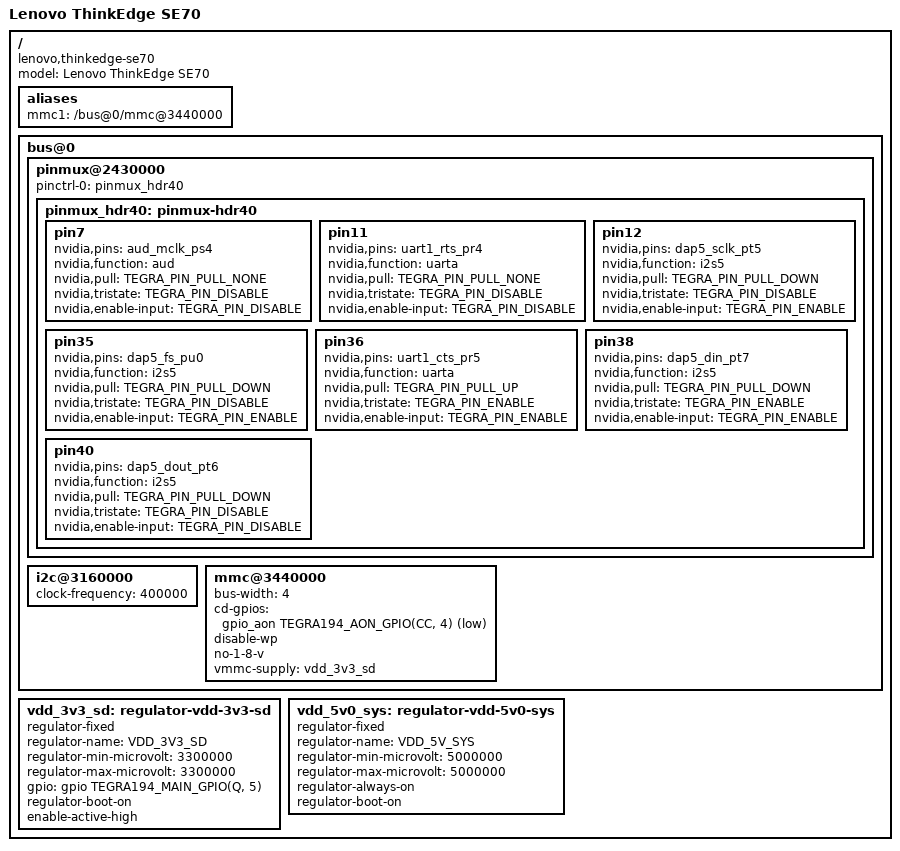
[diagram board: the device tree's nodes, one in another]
// SPDX-License-Identifier: GPL-2.0
/dts-v1/;

#include "tegra194-p3668-0001.dtsi"

#include <dt-bindings/gpio/tegra194-gpio.h>

/ {
	model = "Lenovo ThinkEdge SE70";
	compatible = "lenovo,thinkedge-se70", "nvidia,p3668-0001", "nvidia,tegra194";

	aliases {
		mmc1 = "/bus@0/mmc@3440000";
	};

	bus@0 {
		/* 40-pin expansion header custom pinmux configuration */
		pinmux@2430000 {
			pinctrl-names = "default";
			pinctrl-0 = <&pinmux_hdr40>;

			pinmux_hdr40: pinmux-hdr40 {
				pin7 {
					nvidia,pins = "aud_mclk_ps4";
					nvidia,function = "aud";
					nvidia,pull = <TEGRA_PIN_PULL_NONE>;
					nvidia,tristate = <TEGRA_PIN_DISABLE>;
					nvidia,enable-input = <TEGRA_PIN_DISABLE>;
				};
				pin11 {
					nvidia,pins = "uart1_rts_pr4";
					nvidia,function = "uarta";
					nvidia,pull = <TEGRA_PIN_PULL_NONE>;
					nvidia,tristate = <TEGRA_PIN_DISABLE>;
					nvidia,enable-input = <TEGRA_PIN_DISABLE>;
				};
				pin12 {
					nvidia,pins = "dap5_sclk_pt5";
					nvidia,function = "i2s5";
					nvidia,pull = <TEGRA_PIN_PULL_DOWN>;
					nvidia,tristate = <TEGRA_PIN_DISABLE>;
					nvidia,enable-input = <TEGRA_PIN_ENABLE>;
				};
				pin35 {
					nvidia,pins = "dap5_fs_pu0";
					nvidia,function = "i2s5";
					nvidia,pull = <TEGRA_PIN_PULL_DOWN>;
					nvidia,tristate = <TEGRA_PIN_DISABLE>;
					nvidia,enable-input = <TEGRA_PIN_ENABLE>;
				};
				pin36 {
					nvidia,pins = "uart1_cts_pr5";
					nvidia,function = "uarta";
					nvidia,pull = <TEGRA_PIN_PULL_UP>;
					nvidia,tristate = <TEGRA_PIN_ENABLE>;
					nvidia,enable-input = <TEGRA_PIN_ENABLE>;
				};
				pin38 {
					nvidia,pins = "dap5_din_pt7";
					nvidia,function = "i2s5";
					nvidia,pull = <TEGRA_PIN_PULL_DOWN>;
					nvidia,tristate = <TEGRA_PIN_ENABLE>;
					nvidia,enable-input = <TEGRA_PIN_ENABLE>;
				};
				pin40 {
					nvidia,pins = "dap5_dout_pt6";
					nvidia,function = "i2s5";
					nvidia,pull = <TEGRA_PIN_PULL_DOWN>;
					nvidia,tristate = <TEGRA_PIN_DISABLE>;
					nvidia,enable-input = <TEGRA_PIN_DISABLE>;
				};
			};
		};

		/* Configure i2c bus clock to 400kHz for carrier board peripherals */
		i2c@3160000 {
			clock-frequency = <400000>;
		};

		/* SDMMC3: External Micro SD card slot */
		mmc@3440000 {
			bus-width = <4>;
			cd-gpios = <&gpio_aon TEGRA194_AON_GPIO(CC, 4) GPIO_ACTIVE_LOW>;
			disable-wp;
			no-1-8-v;
			vmmc-supply = <&vdd_3v3_sd>;
			status = "okay";
		};
	};

	/* Fixed 3.3V power supply regulator for external Micro SD slot */
	vdd_3v3_sd: regulator-vdd-3v3-sd {
		compatible = "regulator-fixed";
		regulator-name = "VDD_3V3_SD";
		regulator-min-microvolt = <3300000>;
		regulator-max-microvolt = <3300000>;
		gpio = <&gpio TEGRA194_MAIN_GPIO(Q, 5) GPIO_ACTIVE_HIGH>;
		regulator-boot-on;
		enable-active-high;
	};

	/* System 5V main supply, referenced by SOM and USB nodes */
	vdd_5v0_sys: regulator-vdd-5v0-sys {
		compatible = "regulator-fixed";
		regulator-name = "VDD_5V_SYS";
		regulator-min-microvolt = <5000000>;
		regulator-max-microvolt = <5000000>;
		regulator-always-on;
		regulator-boot-on;
	};
};
